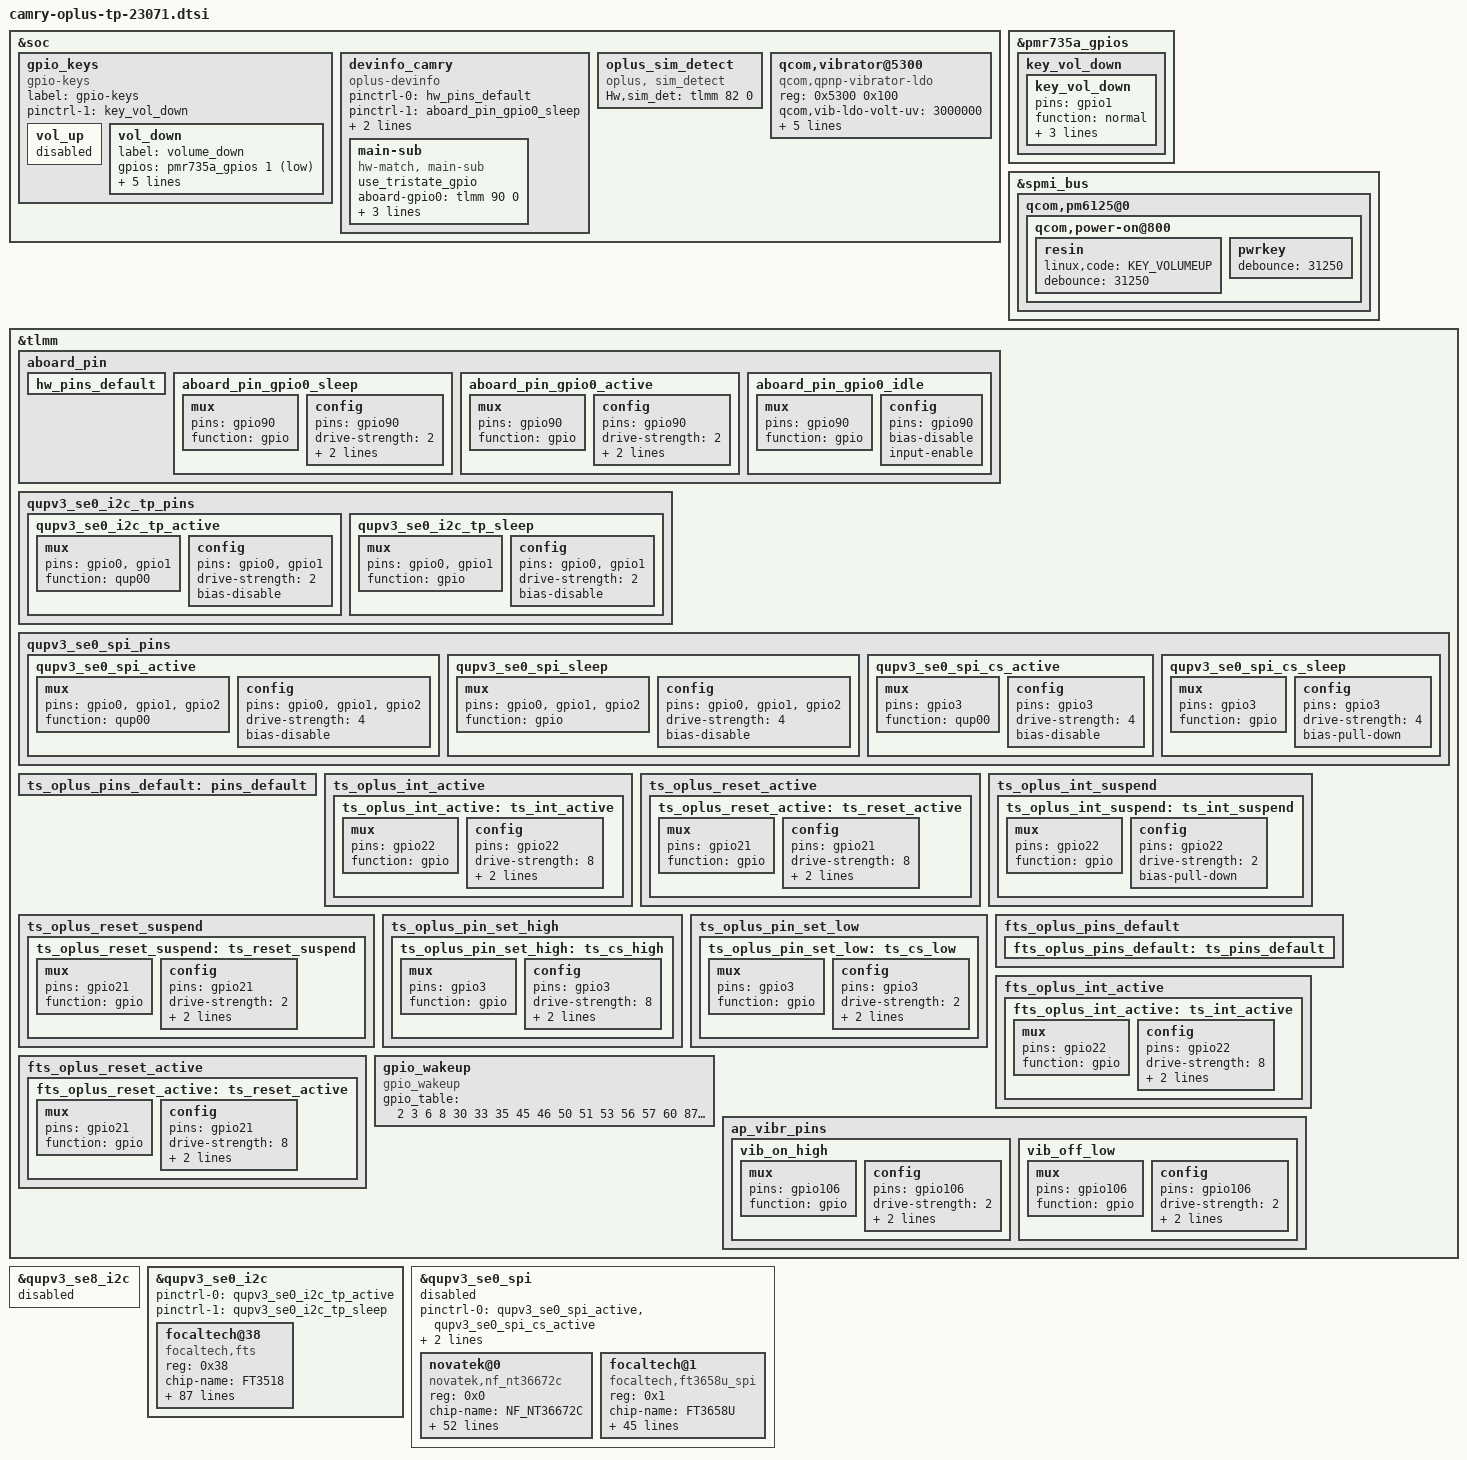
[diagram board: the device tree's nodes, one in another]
/*modfiy for VOLUMEDOWN key*/
&soc {
	gpio_keys {
		compatible = "gpio-keys";
		label = "gpio-keys";
		pinctrl-names = "default";
		pinctrl-1 = <&key_vol_down>;
		/* using volume down config update the default value */
		vol_up {
			status="disabled";
		};
		vol_down {
			label = "volume_down";
			gpios = <&pmr735a_gpios 1 GPIO_ACTIVE_LOW>;
			linux,input-type = <1>;
			linux,code = <KEY_VOLUMEDOWN>;
			gpio-key,wakeup;
			debounce-interval = <32>;
			linux,can-disable;
		};
	};
};
&pmr735a_gpios {
	key_vol_down {
		key_vol_down: key_vol_down {
			pins = "gpio1";
			function = "normal";
			input-enable;
			bias-pull-up;
			power-source = <1>;
		};
	};
};

/*modfiy for VOLUMEUP key*/
&spmi_bus {
	qcom,pm6125@0 {
		qcom,power-on@800 {
			resin {
				linux,code = <KEY_VOLUMEUP>;
				debounce = <31250>;
			};
			pwrkey {
				debounce = <31250>;
			};
		};
	};
};

/*add for subboard match*/
&soc {
	devinfo_camry {
		compatible = "oplus-devinfo";
		pinctrl-names = "default", "sleep", "active", "idle";
		pinctrl-0 = <&hw_pins_default>;
		pinctrl-1 = <&aboard_pin_gpio0_sleep>;
		pinctrl-2 = <&aboard_pin_gpio0_active>;
		pinctrl-3 = <&aboard_pin_gpio0_idle>;

		main-sub {
			compatible = "hw-match, main-sub";
			use_tristate_gpio;
			aboard-gpio0 = <&tlmm 90 0>;
			aboard-patterns = <0 0 1>;	/*0[high-resistance] 1[pull-down] 2[pull-up]*/
			/*region id*/
			region-patterns = <1 2 3>;	/*1[CN] 2[IN] 3[EU] 4[US]*/
			/*main board*/
			match-projects = <23071 23881 23881>;
		};
	};

	oplus_sim_detect {
		compatible = "oplus, sim_detect";
		Hw,sim_det = <&tlmm 82 0>;
	};
};

&tlmm {
	aboard_pin {
		hw_pins_default:hw_pins_default {
		};

		aboard_pin_gpio0_sleep:aboard_pin_gpio0_sleep {
			mux {
				pins = "gpio90";
				function = "gpio";
			};
			config {
				pins = "gpio90";
				drive-strength = <2>;
				bias-pull-down;
				input-enable;
			};
		};

		aboard_pin_gpio0_active:aboard_pin_gpio0_active {
			mux {
				pins = "gpio90";
				function = "gpio";
			};
			config {
				pins = "gpio90";
				drive-strength = <2>;
				bias-pull-up;
				input-enable;
			};
		};

		aboard_pin_gpio0_idle:aboard_pin_gpio0_idle {
			mux {
				pins = "gpio90";
				function = "gpio";
			};
			config {
				pins = "gpio90";
				bias-disable;
				input-enable;
			};
		};
	};
};

/*add for touchpanel device*/
&qupv3_se8_i2c {
	status = "disabled";
};

&qupv3_se0_i2c {
	/delete-property/ pinctrl-0;
	/delete-property/ pinctrl-1;
	pinctrl-0 = <&qupv3_se0_i2c_tp_active>;
	pinctrl-1 = <&qupv3_se0_i2c_tp_sleep>;
};

&qupv3_se0_i2c {
    status = "ok";
    #address-cells = <1>;
    #size-cells = <0>;

    focaltech@38 {
        compatible = "focaltech,fts";
        reg = <0x38>;
        chip-name = "FT3518";
        status = "ok";

        /* Interrupt && Irq-gpio */
        interrupt-parent = <&tlmm>;
        interrupts = <22  0x0>;
        irq-gpio = <&tlmm 22 0x2002>;
        reset-gpio = <&tlmm 21 0x00>;

        /* Power Config */
        enable2v8_gpio = <&tlmm 102 0x1>;
        //enable1v8_gpio = <&tlmm 97 0x1>;
        //vdd_2v8-supply = <&L3C>;
        //vcc_1v8-supply = <&L9A>;
        //vdd_2v8_volt = <3300000>;

        /* Other HW Resource */
        pinctrl-names = "default";
        pinctrl-0 = <&fts_oplus_pins_default>;

        touchpanel,max-num-support = <10>;
        touchpanel,tx-rx-num = <16 34>;
        touchpanel,panel-coords = <8640 19200>;
        touchpanel,display-coords = <1080 2400>;
        touchpanel,touchmajor-limit = <0 54>;
        touchpanel,smooth-level = <255 2 15 25 45 60>;
        touchpanel,smooth-level-charging = <255 15 20 25 45 60>;
        touchpanel,sensitive-level = <255 20 17 14 10 8>;
        touchpanel,high-frame-rate-time = <20>;
        touchpanel,single-optimized-time = <8>;

        panel_type = <8>;
        // type of tp_dev ,TP-SAMSUNG = 8;
        firmware_name = "0xAC570500";
        platform_support_project = <23071 23881>;
        platform_support_project_dir = <23071 23071>;
        platform_support_project_commandline = "default_commandline","default_commandline";

        prevention,curved_screen_V2;
        prevention,grip_disable_level = <6>;
        prevention,updelay_time_ms = <30>;
        prevention,makeup_cnt_weight = <4 1 2 2 2>;
        prevention,large_corner_range = <960 2400>;
        prevention,large_corner_judge_condition = <500 300 800 7 7>;
        prevention,trx_reject_condition = <9 6 7>;
        prevention,trx_strict_reject_condition = <8 5 6>;
        prevention,large_judge_time_ms = <500 50 30>;
        prevention,large_exit_condition = <8 8 2>;
        prevention,single_channel_width = <160 160>;
        prevention,normal_tap_condition = <10 350>;
        prevention,long_edge_condition = <200 80 180 80>;
        prevention,long_strict_edge_condition = <160 60>;
        prevention,long_fingerhold_condition = <50 6 4 4>;
        prevention,short_edge_condition = <200 80 180 80>;
        prevention,short_strict_edge_condition = <160 60>;
        prevention,large_strict_exit_condition = <4 4>;
        prevention,top_corner_config = <440 1200 360>;
        prevention,edge_swipe_config = <240 960>;

        prevention,curved_screen_V4;
        prevention,long_eliminate_point_type = <2 8640 6400 240 19200 300 1>;
        prevention,long_fingerhold_condition2 = <420 0 0 0>;
        prevention,top_corner_config2 = <3 80 480 0 0>;
        prevention,hor_long_top_corner_config = <240 1600 0 0>;
        prevention,top_middle_config = <8640 800 800 0>;
        prevention,corner_eliminate_point_type = <0 960 1600 1>;
        prevention,finger_hold_differ_size = <1 0 240 300>;
        prevention,finger_hold_max_rx_exit_distance = <5 240 1600>;
        prevention,max_rx_exit_distance = <1 5 150 240 1600>;
        prevention,dynamic_finger_hold_exit_distance = <1 240 1600 360>;
        prevention,edge_sliding_matched_support = <1 150 3 0>;

        //grip v4.2 reclining mode -> not support in Camry
        /*prevention,reclining_mode_support = <1>;
        prevention,long_eliminate_point_type_recli = <2 8640 6400 240 19200 500 0>;
        prevention,finger_hold_differ_size_recli = <1 0 240 400>;
        prevention,finger_hold_max_rx_exit_distance_recli = <4 240 1600>;
        prevention,max_rx_exit_distance_recli = <1 4 100 240 1600>;
        prevention,dynamic_finger_hold_exit_distance_recli = <1 240 1600 360>;
        prevention,edge_sliding_matched_support_recli = <1 200 3 0>;
        prevention,long_edge_condition_recli = <160 80 120 80>;*/

        /* SW Support Feature Control */
        black_gesture_support;
        black_gesture_indep_support;
        sportify_aod_gesture_support;
        pressure_report_support;
        charger_pump_support;
        game_switch_support;
        smart_gesture_support;
        fw_update_app_support;
        fingerprint_underscreen_support;
        screenoff_fingerprint_info_support;
        irq_need_dev_resume_ok;
        kernel_grip_support;
        //fw_edge_limit_support;
        exception_upload_support;
        health_monitor_support;
        //focalt x8 resolution config
        high_resolution_support;
        high_resolution_support_x8;
        disable_suspend_irq_handler_support;
        palm_to_sleep_support;
        snr_read_support;
        fingerprint_not_report_in_suspend;
        /*
            *Virtual Key Config:
            *1:touchpanel,button-type: <virtualkey_type  supportted_button-map>
            *virtualkey_type:
            *Type 1: using board_properties
            *Type 2: using same IC (button zone&& touch zone are seprate)
            *Type 3: using diffrent IC (button zone&& touch zone are seprate)
            *Type 4: No need of virtual key process
            *supportted_button-map:select|menu|home|back
            *
            *2:touchpanel,button-map
            *type (X1,Y1)(X2,Y2)(X3,Y3)(Width_X,Hight_Y)--Only when button-type is 0
        */
        touchpanel,button-type = <4>;
        touchpanel.button-TRx = <0 0>;
    };
};

&qupv3_se0_spi {
	/delete-property/ pinctrl-0;
	/delete-property/ pinctrl-1;
	pinctrl-0 = <&qupv3_se0_spi_active &qupv3_se0_spi_cs_active>;
	pinctrl-1 = <&qupv3_se0_spi_sleep &qupv3_se0_spi_cs_sleep>;
};

&qupv3_se0_spi {
    status = "disabled";
    #address-cells = <1>;
    #size-cells = <0>;

    novatek@0 {
        compatible = "novatek,nf_nt36672c";
        reg = <0x0>;
        chip-name = "NF_NT36672C";
        status = "ok";

        spi-max-frequency = <15000000>;    /*4800000,9600000,15000000,19200000*/

        /* Interrupt && Irq-gpio */
        interrupt-parent = <&tlmm>;
        interrupts = <22  0x0>;
        irq-gpio = <&tlmm 22 0x2002>;
        reset-gpio = <&tlmm 21 0x00>;
        cs-gpio = <&tlmm 3 0x00>;

        /* Power Config */
        enable2v8_gpio = <&tlmm 102 0x1>;
        //enable1v8_gpio = <&tlmm 97 0x1>;
        //vdd_2v8-supply = <&L3C>;
        vcc_1v8-supply = <&L13A>;
        //vdd_2v8_volt = <3300000>;

        /* Other HW Resource */
        pinctrl-names = "default",  "oplus_int_active",
		"oplus_reset_active", "oplus_int_suspend",
		"oplus_reset_suspend", "pin_set_high", "pin_set_low";
        pinctrl-0 = <&ts_oplus_pins_default>;
        pinctrl-1 = <&ts_oplus_int_active>;
        pinctrl-2 = <&ts_oplus_reset_active>;
        pinctrl-3 = <&ts_oplus_int_suspend>;
        pinctrl-4 = <&ts_oplus_reset_suspend>;
        pinctrl-5 = <&ts_oplus_pin_set_high>;
        pinctrl-6 = <&ts_oplus_pin_set_low>;

        project_id = <23071>;
        tp_type = <7>;	/*TM*/
        touchpanel,tp-index = <0>;
        panel_type = <7>;
        firmware_name = "0xAC11600";
        touchpanel,irq_need_dev_resume_time = <500>;
        touchpanel,max-num-support = <10>;
        touchpanel,tx-rx-num = <16 36>;
        touchpanel,panel-coords = <4320 9600>;
        touchpanel,display-coords = <1080 2400>;
        touchpanel,touchmajor-limit = <0 54>;
        touchpanel,smooth-level = <255 0 96 192 223 254>;
        touchpanel,smooth-level-charging = <255 0 96 192 223 254>;
        touchpanel,sensitive-level = <255 20 15 10 6 3>;
        touchpanel,single-optimized-time = <8>;

        platform_support_project = <22821 23071 23881>;
        platform_support_project_dir = <23071 23071 23071>;
        platform_support_project_commandline = "default_commandline","default_commandline","default_commandline";

        /* SW Support Feature Control */
        incell_screen;
        irq_need_dev_resume_ok;
        fw_edge_limit_support;
        black_gesture_support;
        charger_pump_support;
        esd_handle_support;
        black_gesture_test_support;
        noflash_support;
        pressure_report_support;
        fw_update_app_support;
        game_switch_support;
        exception_upload_support;
        lcd_trigger_load_tp_fw_support;
        fw_update_in_probe_with_headfile;

        touchpanel,button-type = <4>;
    };

    focaltech@1{
        compatible = "focaltech,ft3658u_spi";
        reg = <0x1>;
        chip-name = "FT3658U";
        status = "ok";

        spi-max-frequency = <6000000>;

        /* Interrupt && Irq-gpio */
        interrupt-parent = <&tlmm>;
        interrupts = <22  0x0>;
        irq-gpio = <&tlmm 22 0x2002>;
        reset-gpio = <&tlmm 21 0x00>;

        /* Power Config */
        enable2v8_gpio = <&tlmm 102 0x1>;
        //enable1v8_gpio = <&tlmm 97 0x1>;
        //vdd_2v8-supply = <&L3C>;
        vcc_1v8-supply = <&L9A>;
        //vdd_2v8_volt = <3300000>;

        /* Other HW Resource */
        pinctrl-names = "default";
        pinctrl-0 = <&fts_oplus_int_active &fts_oplus_reset_active>;

        touchpanel,max-num-support = <10>;
        touchpanel,tx-rx-num = <16 34>;
        touchpanel,panel-coords = <8640 19200>;
        touchpanel,display-coords = <1080 2400>;
        touchpanel,touchmajor-limit = <0 54>;
        touchpanel,smooth-level = <255 15 40 80 160 240>;
        touchpanel,sensitive-level = <255 30 25 20 10 8>;
        touchpanel,high-frame-rate-time = <20>;
        touchpanel,single-optimized-time = <8>;

        panel_type = <8>;
        // type of tp_dev ,TP-SAMSUNG = 8;
        firmware_name = "0xAC570600";
        platform_support_project = <23071 23881>;
        platform_support_project_dir = <23071 23071>;
        platform_support_project_commandline = "default_commandline","default_commandline";

        /* SW Support Feature Control */
        sportify_aod_gesture_support;
        irq_need_dev_resume_ok;
        black_gesture_support;
        fw_edge_limit_support;
        pressure_report_support;
        charger_pump_support;
        game_switch_support;
        smart_gesture_support;
        fw_update_app_support;
        health_monitor_support;
        fingerprint_underscreen_support;
        black_gesture_indep_support;
        exception_upload_support;
        //esd_handle_support;
        new_set_irq_wake_support;
        // focalt x8 resolution config
        high_resolution_support;
        high_resolution_support_x8;
        switch_game_rate_support;
        disable_suspend_irq_handler_support;
        report_rate_game_value = <1>;

        /*
            *Virtual Key Config:
            *1:touchpanel,button-type: <virtualkey_type  supportted_button-map>
            *virtualkey_type:
            *Type 1: using board_properties
            *Type 2: using same IC (button zone&& touch zone are seprate)
            *Type 3: using diffrent IC (button zone&& touch zone are seprate)
            *Type 4: No need of virtual key process
            *supportted_button-map:select|menu|home|back
            *
            *2:touchpanel,button-map
            *type (X1,Y1)(X2,Y2)(X3,Y3)(Width_X,Hight_Y)--Only when button-type is 0
            */
        touchpanel,button-type = <4>;
        touchpanel.button-TRx = <0 0>;
    };
};
#include "camry-23071-nt36672c-tp.dtsi"

/*add for touchpanel spi/i2c bus pins*/
&tlmm {
	qupv3_se0_i2c_tp_pins: qupv3_se0_i2c_tp_pins {
		qupv3_se0_i2c_tp_active: qupv3_se0_i2c_tp_active {
			mux {
				pins = "gpio0", "gpio1";
				function = "qup00";
			};

			config {
				pins = "gpio0", "gpio1";
				drive-strength = <2>;
				bias-disable;
			};
		};

		qupv3_se0_i2c_tp_sleep: qupv3_se0_i2c_tp_sleep {
			mux {
				pins = "gpio0", "gpio1";
				function = "gpio";
			};

			config {
				pins = "gpio0", "gpio1";
				drive-strength = <2>;
				bias-disable;
			};
		};
	};

	qupv3_se0_spi_pins: qupv3_se0_spi_pins {
		qupv3_se0_spi_active: qupv3_se0_spi_active {
			mux {
				pins = "gpio0", "gpio1",
						"gpio2";
				function = "qup00";
			};

			config {
				pins = "gpio0", "gpio1",
						"gpio2";
				drive-strength = <4>;
				bias-disable;
			};
		};
		qupv3_se0_spi_sleep: qupv3_se0_spi_sleep {
			mux {
				pins = "gpio0", "gpio1",
						"gpio2";
				function = "gpio";
			};

			config {
				pins = "gpio0", "gpio1",
						"gpio2";
				drive-strength = <4>;
				bias-disable;
			};
		};
		qupv3_se0_spi_cs_active: qupv3_se0_spi_cs_active {
			mux {
				pins = "gpio3";
				function = "qup00";
			};

			config {
				pins ="gpio3";
				drive-strength = <4>;
				bias-disable;
			};
		};
		qupv3_se0_spi_cs_sleep: qupv3_se0_spi_cs_sleep {
			mux {
				pins = "gpio3";
				function = "gpio";
			};

			config {
				pins = "gpio3";
				drive-strength = <4>;
				bias-pull-down;
			};
		};
	};
};

/*add for touchpanel int/reset/cs pins*/
&tlmm {
	ts_oplus_pins_default: pins_default {
	};

	ts_oplus_int_active {
		ts_oplus_int_active: ts_int_active {
			mux {
				pins = "gpio22";
				function = "gpio";
			};

			config {
				pins = "gpio22";
				drive-strength = <8>;
				bias-pull-up;
				input-enable;
			};
		};
	};

	ts_oplus_reset_active {
		ts_oplus_reset_active: ts_reset_active {
			mux {
				pins = "gpio21";
				function = "gpio";
			};

			config {
				pins = "gpio21";
				drive-strength = <8>;
				output-high;
				bias-pull-up;
			};
		};
	};

	ts_oplus_int_suspend {
		ts_oplus_int_suspend: ts_int_suspend {
			mux {
				pins = "gpio22";
				function = "gpio";
			};

			config {
				pins = "gpio22";
				drive-strength = <2>;
				bias-pull-down;
			};
		};
	};

	ts_oplus_reset_suspend {
		ts_oplus_reset_suspend: ts_reset_suspend {
			mux {
				pins = "gpio21";
				function = "gpio";
			};

			config {
				pins = "gpio21";
				drive-strength = <2>;
				output-low;
				bias-pull-down;
			};
		};
	};

	ts_oplus_pin_set_high {
		ts_oplus_pin_set_high: ts_cs_high {
			mux {
				pins = "gpio3";
				function = "gpio";
			};

			config {
				pins = "gpio3";
				drive-strength = <8>;
				output-high;
				bias-pull-up;
			};
		};
	};

	ts_oplus_pin_set_low {
		ts_oplus_pin_set_low: ts_cs_low {
			mux {
				pins = "gpio3";
				function = "gpio";
			};

			config {
				pins = "gpio3";
				drive-strength = <2>;
				output-low;
				bias-pull-down;
			};
		};
	};

	fts_oplus_pins_default {
		fts_oplus_pins_default: ts_pins_default {
		};
	};

	fts_oplus_int_active {
		fts_oplus_int_active: ts_int_active {
			mux {
				pins = "gpio22";
				function = "gpio";
			};

			config {
				pins = "gpio22";
				drive-strength = <8>;
				bias-pull-up;
				input-enable;
			};
		};
	};

	fts_oplus_reset_active {
		fts_oplus_reset_active: ts_reset_active {
			mux {
				pins = "gpio21";
				function = "gpio";
			};

			config {
				pins = "gpio21";
				drive-strength = <8>;
				output-low;
				bias-disable;
			};
		};
	};
};

/*add for disable wake-up function of NC-GPIO*/
&tlmm {
	gpio_wakeup: gpio_wakeup {
		compatible = "gpio_wakeup";
		gpio_table = <2 3 6 8 30 33 35 45 46 50 51 53 56 57 60 87 89 91 92 96 97 98 107 113 114 115 116 120 125 133 134 154 155>;
	};
};

/*add for vibrator*/
&soc {
	qcom,vibrator@5300 {
		compatible = "qcom,qpnp-vibrator-ldo";
		reg = <0x5300 0x100>;
		qcom,vib-ldo-volt-uv = <3000000>;
		qcom,disable-overdrive;
		qcom,vib-type = <1>;	/*0:ldo 1:gpio*/
		status = "okay";

		qcom,vibrator_switch-gpio = <&tlmm 106 0x00>;
		pinctrl-names = "vib_on_high", "vib_off_low";
		pinctrl-0 = <&vib_on_high>;
		pinctrl-1 = <&vib_off_low >;
	};
};

&tlmm {
	ap_vibr_pins: ap_vibr_pins{
		vib_on_high: vib_on_high{
			mux {
				pins = "gpio106";
				function = "gpio";
			};

			config {
				pins = "gpio106";
				drive-strength = <2>;
				bias-disable;
				output-high;
			};
		};

		vib_off_low: vib_off_low{
			mux {
				pins = "gpio106";
				function = "gpio";
			};

			config {
				pins = "gpio106";
				drive-strength = <2>;
				bias-disable;
				output-low;
			};
		};
	};
};
